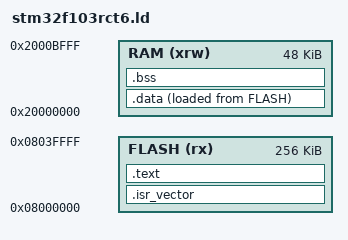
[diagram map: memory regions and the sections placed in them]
/* STM32F103RCT6 — 256 KB Flash, 48 KB SRAM */
MEMORY
{
  FLASH (rx) : ORIGIN = 0x08000000, LENGTH = 256K
  RAM (xrw)  : ORIGIN = 0x20000000, LENGTH = 48K
}

_estack = ORIGIN(RAM) + LENGTH(RAM);

SECTIONS
{
  .isr_vector :
  {
    . = ALIGN(4);
    KEEP(*(.isr_vector))
    . = ALIGN(4);
  } > FLASH

  .text :
  {
    . = ALIGN(4);
    *(.text*)
    *(.rodata*)
    KEEP(*(.init))
    KEEP(*(.fini))
    . = ALIGN(4);
    _etext = .;
  } > FLASH

  .data :
  {
    . = ALIGN(4);
    _sdata = .;
    *(.data*)
    . = ALIGN(4);
    _edata = .;
  } > RAM AT > FLASH
  _sidata = LOADADDR(.data);

  .bss :
  {
    . = ALIGN(4);
    _sbss = .;
    *(.bss*)
    *(COMMON)
    . = ALIGN(4);
    _ebss = .;
  } > RAM

  /DISCARD/ :
  {
    *(.ARM.exidx*)
    *(.eh_frame*)
  }
}
